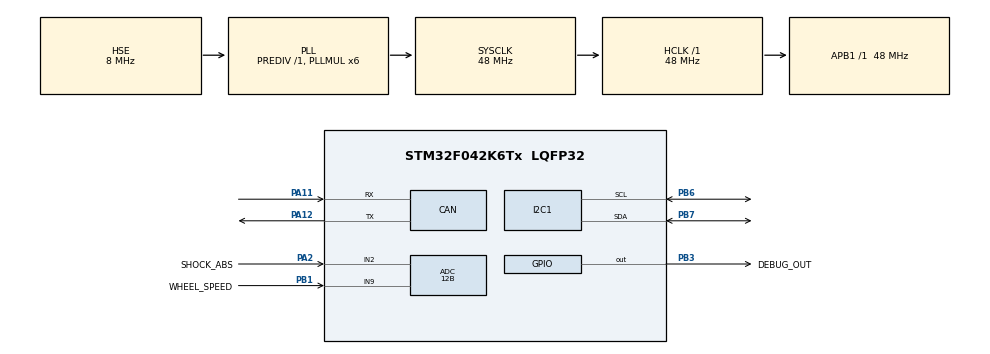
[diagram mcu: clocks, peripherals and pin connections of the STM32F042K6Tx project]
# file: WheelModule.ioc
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ADC.ClockPrescaler=ADC_CLOCK_ASYNC_DIV1
ADC.ContinuousConvMode=ENABLE
ADC.DMAContinuousRequests=ENABLE
ADC.DataAlign=ADC_DATAALIGN_RIGHT
ADC.DiscontinuousConvMode=DISABLE
ADC.EOCSelection=ADC_EOC_SINGLE_CONV
ADC.EnableAnalogWatchDog=false
ADC.ExternalTrigConv=ADC_SOFTWARE_START
ADC.ExternalTrigConvEdge=ADC_EXTERNALTRIGCONVEDGE_NONE
ADC.LowPowerAutoPowerOff=DISABLE
ADC.LowPowerAutoWait=DISABLE
ADC.Overrun=ADC_OVR_DATA_OVERWRITTEN
ADC.Resolution=ADC_RESOLUTION_12B
ADC.SamplingTime=ADC_SAMPLETIME_239CYCLES_5
ADC.ScanConvMode=ADC_SCAN_DIRECTION_FORWARD
CAN.CalculateTimeBit=1000
CAN.CalculateTimeQuantum=333.3333333333333
Dma.ADC.0.Direction=DMA_PERIPH_TO_MEMORY
Dma.ADC.0.Instance=DMA1_Channel1
Dma.ADC.0.MemDataAlignment=DMA_MDATAALIGN_WORD
Dma.ADC.0.MemInc=DMA_MINC_ENABLE
Dma.ADC.0.Mode=DMA_CIRCULAR
Dma.ADC.0.PeriphDataAlignment=DMA_PDATAALIGN_WORD
Dma.ADC.0.PeriphInc=DMA_PINC_DISABLE
Dma.ADC.0.Priority=DMA_PRIORITY_MEDIUM
Dma.Request0=ADC
Mcu.Family=STM32F0
Mcu.Name=STM32F042K6Tx
Mcu.Package=LQFP32
NVIC.DMA1_Channel1_IRQn=true\:0\:0\:false\:false\:true
NVIC.TIM16_IRQn=true\:0\:0\:false\:false\:true
PA11.Mode=Master
PA11.Signal=CAN_RX
PA12.Mode=Master
PA12.Signal=CAN_TX
PA2.GPIO_Label=SHOCK_ABS
PA2.Mode=IN2
PA2.Signal=ADC_IN2
PB1.GPIO_Label=WHEEL_SPEED
PB1.Mode=IN9
PB1.Signal=ADC_IN9
PB3.GPIO_Label=DEBUG_OUT
PB3.GPIO_Speed=GPIO_SPEED_FREQ_HIGH
PB3.Signal=GPIO_Output
PB6.Mode=I2C
PB6.Signal=I2C1_SCL
PB7.Mode=I2C
PB7.Signal=I2C1_SDA
PF0-OSC_IN.Mode=HSE-External-Oscillator
PF0-OSC_IN.Signal=RCC_OSC_IN
PF1-OSC_OUT.Mode=HSE-External-Oscillator
PF1-OSC_OUT.Signal=RCC_OSC_OUT
ProjectManager.HeapSize=0x200
ProjectManager.StackSize=0x400
ProjectManager.TargetToolchain=TrueSTUDIO
RCC.AHBFreq_Value=48000000
RCC.APB1Freq_Value=48000000
RCC.APB1TimFreq_Value=48000000
RCC.EnbaleCSS=true
RCC.HCLKFreq_Value=48000000
RCC.I2c1ClockSelection=RCC_I2C1CLKSOURCE_SYSCLK
RCC.PLLMUL=RCC_PLL_MUL6
RCC.PLLSourceVirtual=RCC_PLLSOURCE_HSE
RCC.SYSCLKFreq_VALUE=48000000
RCC.SYSCLKSource=RCC_SYSCLKSOURCE_PLLCLK
TIM16.Period=25
TIM16.Prescaler=48000
VP_TIM16_VS_ClockSourceINT.Mode=Enable_Timer
board=WheelModule

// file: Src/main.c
/**
  ******************************************************************************
  * File Name          : main.c
  * Description        : Main program body
  ******************************************************************************
  ** This notice applies to any and all portions of this file
  * that are not between comment pairs USER CODE BEGIN and
  * USER CODE END. Other portions of this file, whether
  * inserted by the user or by software development tools
  * are owned by their respective copyright owners.
  *
  * COPYRIGHT(c) 2017 STMicroelectronics
  *
  * Redistribution and use in source and binary forms, with or without modification,
  * are permitted provided that the following conditions are met:
  *   1. Redistributions of source code must retain the above copyright notice,
  *      this list of conditions and the following disclaimer.
  *   2. Redistributions in binary form must reproduce the above copyright notice,
  *      this list of conditions and the following disclaimer in the documentation
  *      and/or other materials provided with the distribution.
  *   3. Neither the name of STMicroelectronics nor the names of its contributors
  *      may be used to endorse or promote products derived from this software
  *      without specific prior written permission.
  *
  * THIS SOFTWARE IS PROVIDED BY THE COPYRIGHT HOLDERS AND CONTRIBUTORS "AS IS"
  * AND ANY EXPRESS OR IMPLIED WARRANTIES, INCLUDING, BUT NOT LIMITED TO, THE
  * IMPLIED WARRANTIES OF MERCHANTABILITY AND FITNESS FOR A PARTICULAR PURPOSE ARE
  * DISCLAIMED. IN NO EVENT SHALL THE COPYRIGHT HOLDER OR CONTRIBUTORS BE LIABLE
  * FOR ANY DIRECT, INDIRECT, INCIDENTAL, SPECIAL, EXEMPLARY, OR CONSEQUENTIAL
  * DAMAGES (INCLUDING, BUT NOT LIMITED TO, PROCUREMENT OF SUBSTITUTE GOODS OR
  * SERVICES; LOSS OF USE, DATA, OR PROFITS; OR BUSINESS INTERRUPTION) HOWEVER
  * CAUSED AND ON ANY THEORY OF LIABILITY, WHETHER IN CONTRACT, STRICT LIABILITY,
  * OR TORT (INCLUDING NEGLIGENCE OR OTHERWISE) ARISING IN ANY WAY OUT OF THE USE
  * OF THIS SOFTWARE, EVEN IF ADVISED OF THE POSSIBILITY OF SUCH DAMAGE.
  *
  ******************************************************************************
  */
#include "main.h"
#include "stm32f0xx_hal.h"
#include "adc.h"
#include "can.h"
#include "dma.h"
#include "i2c.h"
#include "tim.h"
#include "gpio.h"

/* USER CODE BEGIN PV */
/* Private variables ---------------------------------------------------------*/

/* USER CODE END PV */

void SystemClock_Config(void);

/* USER CODE BEGIN PFP */
/* Private function prototypes -----------------------------------------------*/

/* USER CODE END PFP */

int main(void)
{

  /* MCU Configuration----------------------------------------------------------*/

  /* Reset of all peripherals, Initializes the Flash interface and the Systick. */
  HAL_Init();

  /* Configure the system clock */
  SystemClock_Config();

  /* Initialize all configured peripherals */
  MX_GPIO_Init();
  MX_DMA_Init();
  MX_ADC_Init();
  MX_CAN_Init();
  MX_I2C1_Init();
  MX_TIM16_Init();

  /* USER CODE BEGIN 2 */

  INIT_ADC_SENSORS_DMA(&hadc,&adc_conv_results[0],NUM_OF_CONV);

  //if( HAL_ADC_Start(&hadc1) != HAL_OK){
//	  return 0;
  //}

  //if (HAL_ADC_Start_DMA(&hadc1, (uint16_t*)&shock_adc_regval, 1) != HAL_OK){
	//  return 0;
  //}

  /* USER CODE END 2 */

  /* Infinite loop */
  while (1)
  {

  }

}

/** System Clock Configuration
*/
void SystemClock_Config(void)
{

  RCC_OscInitTypeDef RCC_OscInitStruct;
  RCC_ClkInitTypeDef RCC_ClkInitStruct;
  RCC_PeriphCLKInitTypeDef PeriphClkInit;

    /**Initializes the CPU, AHB and APB busses clocks
    */
  RCC_OscInitStruct.OscillatorType = RCC_OSCILLATORTYPE_HSI14|RCC_OSCILLATORTYPE_HSE;
  RCC_OscInitStruct.HSEState = RCC_HSE_ON;
  RCC_OscInitStruct.HSIState = RCC_HSI_ON;
  RCC_OscInitStruct.HSI14State = RCC_HSI14_ON;
  RCC_OscInitStruct.HSI14CalibrationValue = 16;
  RCC_OscInitStruct.PLL.PLLState = RCC_PLL_ON;
  RCC_OscInitStruct.PLL.PLLSource = RCC_PLLSOURCE_HSE;
  RCC_OscInitStruct.PLL.PLLMUL = RCC_PLL_MUL6;
  RCC_OscInitStruct.PLL.PREDIV = RCC_PREDIV_DIV1;
  if (HAL_RCC_OscConfig(&RCC_OscInitStruct) != HAL_OK)
  {
    _Error_Handler(__FILE__, __LINE__);
  }

    /**Initializes the CPU, AHB and APB busses clocks
    */
  RCC_ClkInitStruct.ClockType = RCC_CLOCKTYPE_HCLK|RCC_CLOCKTYPE_SYSCLK
                              |RCC_CLOCKTYPE_PCLK1;
  RCC_ClkInitStruct.SYSCLKSource = RCC_SYSCLKSOURCE_PLLCLK;
  RCC_ClkInitStruct.AHBCLKDivider = RCC_SYSCLK_DIV1;
  RCC_ClkInitStruct.APB1CLKDivider = RCC_HCLK_DIV1;

  if (HAL_RCC_ClockConfig(&RCC_ClkInitStruct, FLASH_LATENCY_1) != HAL_OK)
  {
    _Error_Handler(__FILE__, __LINE__);
  }

  PeriphClkInit.PeriphClockSelection = RCC_PERIPHCLK_I2C1;
  PeriphClkInit.I2c1ClockSelection = RCC_I2C1CLKSOURCE_SYSCLK;
  if (HAL_RCCEx_PeriphCLKConfig(&PeriphClkInit) != HAL_OK)
  {
    _Error_Handler(__FILE__, __LINE__);
  }

    /**Enables the Clock Security System
    */
  HAL_RCC_EnableCSS();

    /**Configure the Systick interrupt time
    */
  HAL_SYSTICK_Config(HAL_RCC_GetHCLKFreq()/1000);

    /**Configure the Systick
    */
  HAL_SYSTICK_CLKSourceConfig(SYSTICK_CLKSOURCE_HCLK);

  /* SysTick_IRQn interrupt configuration */
  HAL_NVIC_SetPriority(SysTick_IRQn, 0, 0);
}

void _Error_Handler(char * file, int line)
{
  while(1)
  {
  }
}

/************************ (C) COPYRIGHT STMicroelectronics *****END OF FILE****/
